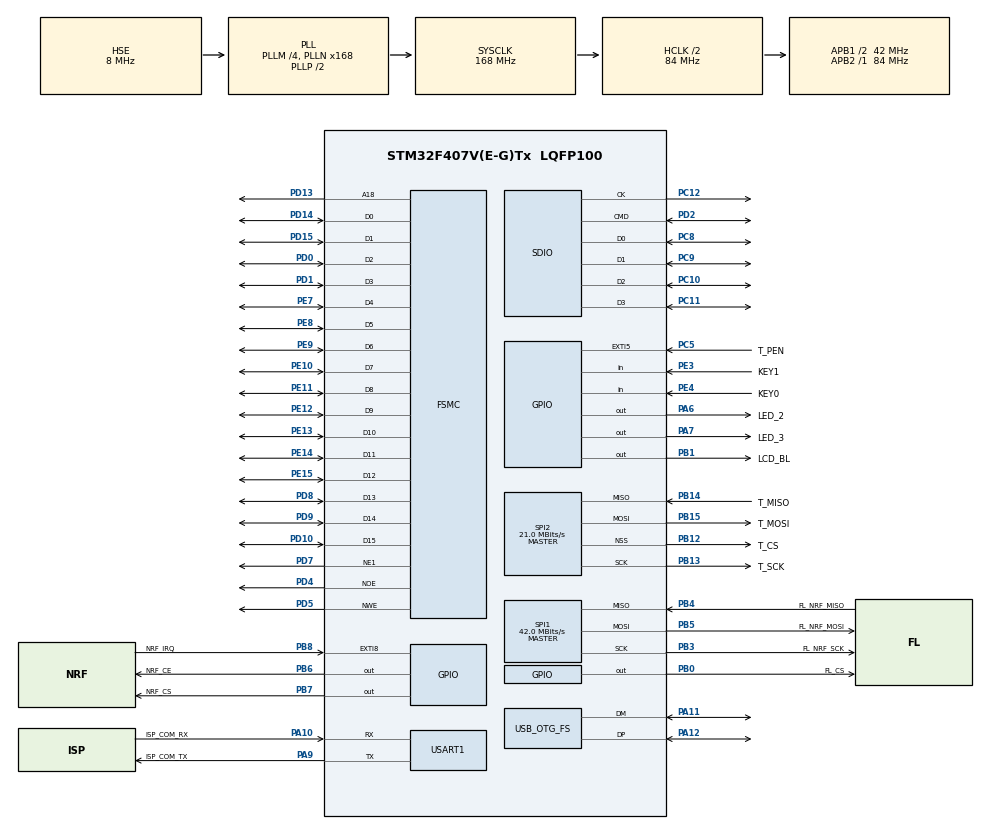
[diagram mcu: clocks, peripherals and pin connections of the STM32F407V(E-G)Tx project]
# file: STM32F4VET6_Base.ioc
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Mcu.Family=STM32F4
PD7.Mode=NorPsramChipSelect1_1
USB_DEVICE.CLASS_NAME_FS=CDC
PH0-OSC_IN.Signal=RCC_OSC_IN
SPI2.VirtualNSS=VM_NSSHARD
RCC.CortexFreq_Value=84000000
SPI1.VirtualType=VM_MASTER
SPI2.VirtualType=VM_MASTER
PC10.Signal=SDIO_D2
PC12.Signal=SDIO_CK
PB14.GPIO_Label=T_MISO
PA11.Mode=Device_Only
PB0.GPIO_Label=FL_CS
PA6.GPIO_Label=LED_2
PB6.GPIO_Label=NRF_CE
USB_DEVICE.VirtualMode-CDC_FS=Cdc
PB13.GPIO_Label=T_SCK
PB13.Signal=SPI2_SCK
PB15.Signal=SPI2_MOSI
PD9.Mode=16b-d1
RCC.SYSCLKSource=RCC_SYSCLKSOURCE_PLLCLK
ProjectManager.StackSize=0x400
VP_FREERTOS_VS_CMSIS_V2.Mode=CMSIS_V2
PD13.Signal=FSMC_A18
FREERTOS.configENABLE_FPU=1
PA12.Signal=USB_OTG_FS_DP
PE11.Mode=16b-d1
RCC.RCC_RTC_Clock_Source=RCC_RTCCLKSOURCE_LSE
SPI1.Direction=SPI_DIRECTION_2LINES
RCC.HCLKFreq_Value=84000000
PD4.Signal=FSMC_NOE
RCC.APB2TimFreq_Value=84000000
PB6.Signal=GPIO_Output
SPI1.CalculateBaudRate=42.0 MBits/s
PD10.Mode=16b-d1
PD0.Signal=FSMC_D2
PD8.Signal=FSMC_D13
RCC.AHBFreq_Value=84000000
SPI2.BaudRatePrescaler=SPI_BAUDRATEPRESCALER_2
PH0-OSC_IN.Mode=HSE-External-Oscillator
PD5.Mode=Lcd1
RCC.HSE_VALUE=8000000
PB3.Mode=Full_Duplex_Master
PB12.GPIO_Label=T_CS
PB4.Mode=Full_Duplex_Master
PE13.Signal=FSMC_D10
PC14-OSC32_IN.Mode=LSE-External-Oscillator
PE9.Signal=FSMC_D6
PA14.Mode=Serial_Wire
PD14.Mode=16b-d1
PB14.Mode=Full_Duplex_Master
VP_SYS_VS_tim1.Mode=TIM1
PB1.GPIO_Label=LCD_BL
PB5.Mode=Full_Duplex_Master
PA10.GPIO_Label=ISP_COM_RX
PE4.GPIO_Label=KEY0
PC9.Mode=SD_4_bits_Wide_bus
SPI2.CalculateBaudRate=21.0 MBits/s
PB7.Signal=GPIO_Output
PE13.Mode=16b-d1
PE4.Signal=GPIO_Input
PE10.Signal=FSMC_D7
USB_DEVICE.APP_RX_DATA_SIZE-CDC_FS=128
PH1-OSC_OUT.Mode=HSE-External-Oscillator
PD15.Mode=16b-d1
PB7.GPIO_Label=NRF_CS
Mcu.Package=LQFP100
PB1.Signal=GPIO_Output
PA6.Signal=GPIO_Output
PB12.Mode=NSS_Signal_Hard_Output
FREERTOS.configUSE_NEWLIB_REENTRANT=0
NVIC.TimeBase=TIM1_UP_TIM10_IRQn
SPI2.Mode=SPI_MODE_MASTER
NVIC.OTG_FS_IRQn=true\:0\:0\:false\:false\:true\:false\:false\:true
NVIC.TimeBaseIP=TIM1
PA10.Signal=USART1_RX
USB_OTG_FS.VirtualMode=Device_Only
PE9.Mode=16b-d1
PC11.Mode=SD_4_bits_Wide_bus
PB5.GPIO_Label=FL_NRF_MOSI
PD4.Mode=Lcd1
RCC.APB1TimFreq_Value=84000000
SPI2.Direction=SPI_DIRECTION_2LINES
PC5.Signal=GPXTI5
PB13.Mode=Full_Duplex_Master
PE7.Signal=FSMC_D4
SPI1.BaudRatePrescaler=SPI_BAUDRATEPRESCALER_2
PD15.Signal=FSMC_D1
PB4.Signal=SPI1_MISO
PE12.Mode=16b-d1
PB3.GPIO_Label=FL_NRF_SCK
PC15-OSC32_OUT.Mode=LSE-External-Oscillator
FREERTOS.Tasks01=defaultTask,24,128,StartDefaultTask,As weak,NULL,Static,defaultTaskBuffer,defaultTaskControlBlock;myTask02,8,128,StartTask02,As weak,NULL,Static,myTask02Buffer,myTask02ControlBlock
PA10.Mode=Asynchronous
USB_DEVICE.VirtualModeFS=Cdc_FS
PC11.Signal=SDIO_D3
PA9.GPIO_Label=ISP_COM_TX
PC8.Signal=SDIO_D0
PE10.Mode=16b-d1
PC10.Mode=SD_4_bits_Wide_bus
PD7.Signal=FSMC_NE1
PD1.Signal=FSMC_D3
PD9.Signal=FSMC_D14
PD5.Signal=FSMC_NWE
RCC.APB1CLKDivider=RCC_HCLK_DIV2
PC14-OSC32_IN.Signal=RCC_OSC32_IN
PA0-WKUP.GPIO_Label=KEY_UP
PA0-WKUP.Signal=SYS_WKUP
PE8.Mode=16b-d1
PA0-WKUP.Mode=SYS_WakeUp0
PD10.Signal=FSMC_D15
PA13.Signal=SYS_JTMS-SWDIO
PB8.GPIO_Label=NRF_IRQ
PA9.Mode=Asynchronous
ProjectManager.TargetToolchain=STM32CubeIDE
USB_DEVICE.APP_TX_DATA_SIZE-CDC_FS=128
VP_USB_DEVICE_VS_USB_DEVICE_CDC_FS.Mode=CDC_FS
PA9.Signal=USART1_TX
PD13.Mode=A18_1
PE11.Signal=FSMC_D8
PC15-OSC32_OUT.Signal=RCC_OSC32_OUT
PD8.Mode=16b-d1
PB14.Signal=SPI2_MISO
PD2.Mode=SD_4_bits_Wide_bus
PC12.Mode=SD_4_bits_Wide_bus
board=custom
RCC.VCOOutputFreq_Value=336000000
PB15.Mode=Full_Duplex_Master
PD1.Mode=16b-d1
RCC.APB2Freq_Value=84000000
PE14.Signal=FSMC_D11
PE15.Signal=FSMC_D12
PB4.GPIO_Label=FL_NRF_MISO
PB15.GPIO_Label=T_MOSI
PE8.Signal=FSMC_D5
SPI1.Mode=SPI_MODE_MASTER
PE14.Mode=16b-d1
PH1-OSC_OUT.Signal=RCC_OSC_OUT
RCC.RCC_RTC_Clock_SourceVirtual=RCC_RTCCLKSOURCE_LSE
RCC.AHBCLKDivider=RCC_SYSCLK_DIV2
PA13.Mode=Serial_Wire
Mcu.Name=STM32F407V(E-G)Tx
PD0.Mode=16b-d1
PE12.Signal=FSMC_D9
PD14.Signal=FSMC_D0
PC8.Mode=SD_4_bits_Wide_bus
RCC.48MHZClocksFreq_Value=48000000
PB3.Signal=SPI1_SCK
RCC.SYSCLKFreq_VALUE=168000000
PE7.Mode=16b-d1
PB5.Signal=SPI1_MOSI
PA7.GPIO_Label=LED_3
PA12.Mode=Device_Only
PC5.GPIO_Label=T_PEN
USART1.VirtualMode=VM_ASYNC
PA11.Signal=USB_OTG_FS_DM
PA14.Signal=SYS_JTCK-SWCLK
ProjectManager.HeapSize=0x200
NVIC.TIM1_UP_TIM10_IRQn=true\:0\:0\:false\:false\:true\:false\:false\:true
RCC.HSI_VALUE=16000000
RCC.PLLQ=7
NVIC.PriorityGroup=NVIC_PRIORITYGROUP_4
RCC.PLLM=4
RCC.PLLN=168
PE3.Signal=GPIO_Input
PB8.Signal=GPXTI8
PE3.GPIO_Label=KEY1
PC9.Signal=SDIO_D1
PD2.Signal=SDIO_CMD
RCC.APB1Freq_Value=42000000
PB0.Signal=GPIO_Output
PB12.Signal=SPI2_NSS
PE15.Mode=16b-d1
PA7.Signal=GPIO_Output

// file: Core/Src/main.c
/* USER CODE BEGIN Header */
/**
  ******************************************************************************
  * @file           : main.c
  * @brief          : Main program body
  ******************************************************************************
  * @attention
  *
  * <h2><center>&copy; Copyright (c) 2020 STMicroelectronics.
  * All rights reserved.</center></h2>
  *
  * This software component is licensed by ST under BSD 3-Clause license,
  * the "License"; You may not use this file except in compliance with the
  * License. You may obtain a copy of the License at:
  *                        opensource.org/licenses/BSD-3-Clause
  *
  ******************************************************************************
  */
/* USER CODE END Header */
#include "main.h"
#include "cmsis_os.h"
#include "usb_device.h"

/* USER CODE BEGIN Includes */
#include <usbd_cdc_if.h>
/* USER CODE END Includes */

typedef StaticTask_t osStaticThreadDef_t;

SD_HandleTypeDef hsd;

SPI_HandleTypeDef hspi1;
SPI_HandleTypeDef hspi2;

UART_HandleTypeDef huart1;

SRAM_HandleTypeDef hsram1;

/* Definitions for defaultTask */
osThreadId_t defaultTaskHandle;
uint32_t defaultTaskBuffer[ 128 ];
osStaticThreadDef_t defaultTaskControlBlock;
const osThreadAttr_t defaultTask_attributes = {
  .name = "defaultTask",
  .stack_mem = &defaultTaskBuffer[0],
  .stack_size = sizeof(defaultTaskBuffer),
  .cb_mem = &defaultTaskControlBlock,
  .cb_size = sizeof(defaultTaskControlBlock),
  .priority = (osPriority_t) osPriorityNormal,
};
/* Definitions for myTask02 */
osThreadId_t myTask02Handle;
uint32_t myTask02Buffer[ 128 ];
osStaticThreadDef_t myTask02ControlBlock;
const osThreadAttr_t myTask02_attributes = {
  .name = "myTask02",
  .stack_mem = &myTask02Buffer[0],
  .stack_size = sizeof(myTask02Buffer),
  .cb_mem = &myTask02ControlBlock,
  .cb_size = sizeof(myTask02ControlBlock),
  .priority = (osPriority_t) osPriorityLow,
};

void SystemClock_Config(void);
static void MX_GPIO_Init(void);
static void MX_FSMC_Init(void);
static void MX_SDIO_SD_Init(void);
static void MX_SPI1_Init(void);
static void MX_SPI2_Init(void);
static void MX_USART1_UART_Init(void);
void StartDefaultTask(void *argument);
void StartTask02(void *argument);

int main(void)
{

  /* MCU Configuration--------------------------------------------------------*/

  /* Reset of all peripherals, Initializes the Flash interface and the Systick. */
  HAL_Init();

  /* Configure the system clock */
  SystemClock_Config();

  /* Initialize all configured peripherals */
  MX_GPIO_Init();
  MX_FSMC_Init();
  MX_SDIO_SD_Init();
  MX_SPI1_Init();
  MX_SPI2_Init();
  MX_USART1_UART_Init();

  /* Init scheduler */
  osKernelInitialize();

  /* Create the thread(s) */
  /* creation of defaultTask */
  defaultTaskHandle = osThreadNew(StartDefaultTask, NULL, &defaultTask_attributes);

  /* creation of myTask02 */
  myTask02Handle = osThreadNew(StartTask02, NULL, &myTask02_attributes);

  /* Start scheduler */
  osKernelStart();

  /* We should never get here as control is now taken by the scheduler */
  /* Infinite loop */
  while (1)
  {

  }
}

void SystemClock_Config(void)
{
  RCC_OscInitTypeDef RCC_OscInitStruct = {0};
  RCC_ClkInitTypeDef RCC_ClkInitStruct = {0};

  /** Configure the main internal regulator output voltage
  */
  __HAL_RCC_PWR_CLK_ENABLE();
  __HAL_PWR_VOLTAGESCALING_CONFIG(PWR_REGULATOR_VOLTAGE_SCALE1);
  /** Initializes the RCC Oscillators according to the specified parameters
  * in the RCC_OscInitTypeDef structure.
  */
  RCC_OscInitStruct.OscillatorType = RCC_OSCILLATORTYPE_HSE;
  RCC_OscInitStruct.HSEState = RCC_HSE_ON;
  RCC_OscInitStruct.PLL.PLLState = RCC_PLL_ON;
  RCC_OscInitStruct.PLL.PLLSource = RCC_PLLSOURCE_HSE;
  RCC_OscInitStruct.PLL.PLLM = 4;
  RCC_OscInitStruct.PLL.PLLN = 168;
  RCC_OscInitStruct.PLL.PLLP = RCC_PLLP_DIV2;
  RCC_OscInitStruct.PLL.PLLQ = 7;
  if (HAL_RCC_OscConfig(&RCC_OscInitStruct) != HAL_OK)
  {
    Error_Handler();
  }
  /** Initializes the CPU, AHB and APB buses clocks
  */
  RCC_ClkInitStruct.ClockType = RCC_CLOCKTYPE_HCLK|RCC_CLOCKTYPE_SYSCLK
                              |RCC_CLOCKTYPE_PCLK1|RCC_CLOCKTYPE_PCLK2;
  RCC_ClkInitStruct.SYSCLKSource = RCC_SYSCLKSOURCE_PLLCLK;
  RCC_ClkInitStruct.AHBCLKDivider = RCC_SYSCLK_DIV2;
  RCC_ClkInitStruct.APB1CLKDivider = RCC_HCLK_DIV2;
  RCC_ClkInitStruct.APB2CLKDivider = RCC_HCLK_DIV1;

  if (HAL_RCC_ClockConfig(&RCC_ClkInitStruct, FLASH_LATENCY_2) != HAL_OK)
  {
    Error_Handler();
  }
}

static void MX_SDIO_SD_Init(void)
{

  hsd.Instance = SDIO;
  hsd.Init.ClockEdge = SDIO_CLOCK_EDGE_RISING;
  hsd.Init.ClockBypass = SDIO_CLOCK_BYPASS_DISABLE;
  hsd.Init.ClockPowerSave = SDIO_CLOCK_POWER_SAVE_DISABLE;
  hsd.Init.BusWide = SDIO_BUS_WIDE_1B;
  hsd.Init.HardwareFlowControl = SDIO_HARDWARE_FLOW_CONTROL_DISABLE;
  hsd.Init.ClockDiv = 0;
  if (HAL_SD_Init(&hsd) != HAL_OK)
  {
    Error_Handler();
  }
  if (HAL_SD_ConfigWideBusOperation(&hsd, SDIO_BUS_WIDE_4B) != HAL_OK)
  {
    Error_Handler();
  }

}

static void MX_SPI1_Init(void)
{

  /* SPI1 parameter configuration*/
  hspi1.Instance = SPI1;
  hspi1.Init.Mode = SPI_MODE_MASTER;
  hspi1.Init.Direction = SPI_DIRECTION_2LINES;
  hspi1.Init.DataSize = SPI_DATASIZE_8BIT;
  hspi1.Init.CLKPolarity = SPI_POLARITY_LOW;
  hspi1.Init.CLKPhase = SPI_PHASE_1EDGE;
  hspi1.Init.NSS = SPI_NSS_SOFT;
  hspi1.Init.BaudRatePrescaler = SPI_BAUDRATEPRESCALER_2;
  hspi1.Init.FirstBit = SPI_FIRSTBIT_MSB;
  hspi1.Init.TIMode = SPI_TIMODE_DISABLE;
  hspi1.Init.CRCCalculation = SPI_CRCCALCULATION_DISABLE;
  hspi1.Init.CRCPolynomial = 10;
  if (HAL_SPI_Init(&hspi1) != HAL_OK)
  {
    Error_Handler();
  }

}

static void MX_SPI2_Init(void)
{

  /* SPI2 parameter configuration*/
  hspi2.Instance = SPI2;
  hspi2.Init.Mode = SPI_MODE_MASTER;
  hspi2.Init.Direction = SPI_DIRECTION_2LINES;
  hspi2.Init.DataSize = SPI_DATASIZE_8BIT;
  hspi2.Init.CLKPolarity = SPI_POLARITY_LOW;
  hspi2.Init.CLKPhase = SPI_PHASE_1EDGE;
  hspi2.Init.NSS = SPI_NSS_HARD_OUTPUT;
  hspi2.Init.BaudRatePrescaler = SPI_BAUDRATEPRESCALER_2;
  hspi2.Init.FirstBit = SPI_FIRSTBIT_MSB;
  hspi2.Init.TIMode = SPI_TIMODE_DISABLE;
  hspi2.Init.CRCCalculation = SPI_CRCCALCULATION_DISABLE;
  hspi2.Init.CRCPolynomial = 10;
  if (HAL_SPI_Init(&hspi2) != HAL_OK)
  {
    Error_Handler();
  }

}

static void MX_USART1_UART_Init(void)
{

  huart1.Instance = USART1;
  huart1.Init.BaudRate = 115200;
  huart1.Init.WordLength = UART_WORDLENGTH_8B;
  huart1.Init.StopBits = UART_STOPBITS_1;
  huart1.Init.Parity = UART_PARITY_NONE;
  huart1.Init.Mode = UART_MODE_TX_RX;
  huart1.Init.HwFlowCtl = UART_HWCONTROL_NONE;
  huart1.Init.OverSampling = UART_OVERSAMPLING_16;
  if (HAL_UART_Init(&huart1) != HAL_OK)
  {
    Error_Handler();
  }

}

static void MX_GPIO_Init(void)
{
  GPIO_InitTypeDef GPIO_InitStruct = {0};

  /* GPIO Ports Clock Enable */
  __HAL_RCC_GPIOE_CLK_ENABLE();
  __HAL_RCC_GPIOC_CLK_ENABLE();
  __HAL_RCC_GPIOH_CLK_ENABLE();
  __HAL_RCC_GPIOA_CLK_ENABLE();
  __HAL_RCC_GPIOB_CLK_ENABLE();
  __HAL_RCC_GPIOD_CLK_ENABLE();

  /*Configure GPIO pin Output Level */
  HAL_GPIO_WritePin(GPIOA, LED_2_Pin|LED_3_Pin, GPIO_PIN_RESET);

  /*Configure GPIO pin Output Level */
  HAL_GPIO_WritePin(GPIOB, FL_CS_Pin|LCD_BL_Pin|NRF_CE_Pin|NRF_CS_Pin, GPIO_PIN_RESET);

  /*Configure GPIO pins : KEY1_Pin KEY0_Pin */
  GPIO_InitStruct.Pin = KEY1_Pin|KEY0_Pin;
  GPIO_InitStruct.Mode = GPIO_MODE_INPUT;
  GPIO_InitStruct.Pull = GPIO_NOPULL;
  HAL_GPIO_Init(GPIOE, &GPIO_InitStruct);

  /*Configure GPIO pins : LED_2_Pin LED_3_Pin */
  GPIO_InitStruct.Pin = LED_2_Pin|LED_3_Pin;
  GPIO_InitStruct.Mode = GPIO_MODE_OUTPUT_PP;
  GPIO_InitStruct.Pull = GPIO_NOPULL;
  GPIO_InitStruct.Speed = GPIO_SPEED_FREQ_LOW;
  HAL_GPIO_Init(GPIOA, &GPIO_InitStruct);

  /*Configure GPIO pin : T_PEN_Pin */
  GPIO_InitStruct.Pin = T_PEN_Pin;
  GPIO_InitStruct.Mode = GPIO_MODE_IT_RISING;
  GPIO_InitStruct.Pull = GPIO_NOPULL;
  HAL_GPIO_Init(T_PEN_GPIO_Port, &GPIO_InitStruct);

  /*Configure GPIO pins : FL_CS_Pin LCD_BL_Pin NRF_CE_Pin NRF_CS_Pin */
  GPIO_InitStruct.Pin = FL_CS_Pin|LCD_BL_Pin|NRF_CE_Pin|NRF_CS_Pin;
  GPIO_InitStruct.Mode = GPIO_MODE_OUTPUT_PP;
  GPIO_InitStruct.Pull = GPIO_NOPULL;
  GPIO_InitStruct.Speed = GPIO_SPEED_FREQ_LOW;
  HAL_GPIO_Init(GPIOB, &GPIO_InitStruct);

  /*Configure GPIO pin : NRF_IRQ_Pin */
  GPIO_InitStruct.Pin = NRF_IRQ_Pin;
  GPIO_InitStruct.Mode = GPIO_MODE_IT_RISING;
  GPIO_InitStruct.Pull = GPIO_NOPULL;
  HAL_GPIO_Init(NRF_IRQ_GPIO_Port, &GPIO_InitStruct);

}

/* FSMC initialization function */
static void MX_FSMC_Init(void)
{

  FSMC_NORSRAM_TimingTypeDef Timing = {0};

  /** Perform the SRAM1 memory initialization sequence
  */
  hsram1.Instance = FSMC_NORSRAM_DEVICE;
  hsram1.Extended = FSMC_NORSRAM_EXTENDED_DEVICE;
  /* hsram1.Init */
  hsram1.Init.NSBank = FSMC_NORSRAM_BANK1;
  hsram1.Init.DataAddressMux = FSMC_DATA_ADDRESS_MUX_DISABLE;
  hsram1.Init.MemoryType = FSMC_MEMORY_TYPE_SRAM;
  hsram1.Init.MemoryDataWidth = FSMC_NORSRAM_MEM_BUS_WIDTH_16;
  hsram1.Init.BurstAccessMode = FSMC_BURST_ACCESS_MODE_DISABLE;
  hsram1.Init.WaitSignalPolarity = FSMC_WAIT_SIGNAL_POLARITY_LOW;
  hsram1.Init.WrapMode = FSMC_WRAP_MODE_DISABLE;
  hsram1.Init.WaitSignalActive = FSMC_WAIT_TIMING_BEFORE_WS;
  hsram1.Init.WriteOperation = FSMC_WRITE_OPERATION_ENABLE;
  hsram1.Init.WaitSignal = FSMC_WAIT_SIGNAL_DISABLE;
  hsram1.Init.ExtendedMode = FSMC_EXTENDED_MODE_DISABLE;
  hsram1.Init.AsynchronousWait = FSMC_ASYNCHRONOUS_WAIT_DISABLE;
  hsram1.Init.WriteBurst = FSMC_WRITE_BURST_DISABLE;
  hsram1.Init.PageSize = FSMC_PAGE_SIZE_NONE;
  /* Timing */
  Timing.AddressSetupTime = 15;
  Timing.AddressHoldTime = 15;
  Timing.DataSetupTime = 255;
  Timing.BusTurnAroundDuration = 15;
  Timing.CLKDivision = 16;
  Timing.DataLatency = 17;
  Timing.AccessMode = FSMC_ACCESS_MODE_A;
  /* ExtTiming */

  if (HAL_SRAM_Init(&hsram1, &Timing, NULL) != HAL_OK)
  {
    Error_Handler( );
  }

}

__weak void StartDefaultTask(void *argument)
{
  /* init code for USB_DEVICE */
  MX_USB_DEVICE_Init();
  for(;;)
  {
    osDelay(1);
  }
}

__weak void StartTask02(void *argument)
{
  for(;;)
  {
    osDelay(1);
  }
}

void HAL_TIM_PeriodElapsedCallback(TIM_HandleTypeDef *htim)
{
  if (htim->Instance == TIM1) {
    HAL_IncTick();
  }
}

void Error_Handler(void)
{
}

/************************ (C) COPYRIGHT STMicroelectronics *****END OF FILE****/
